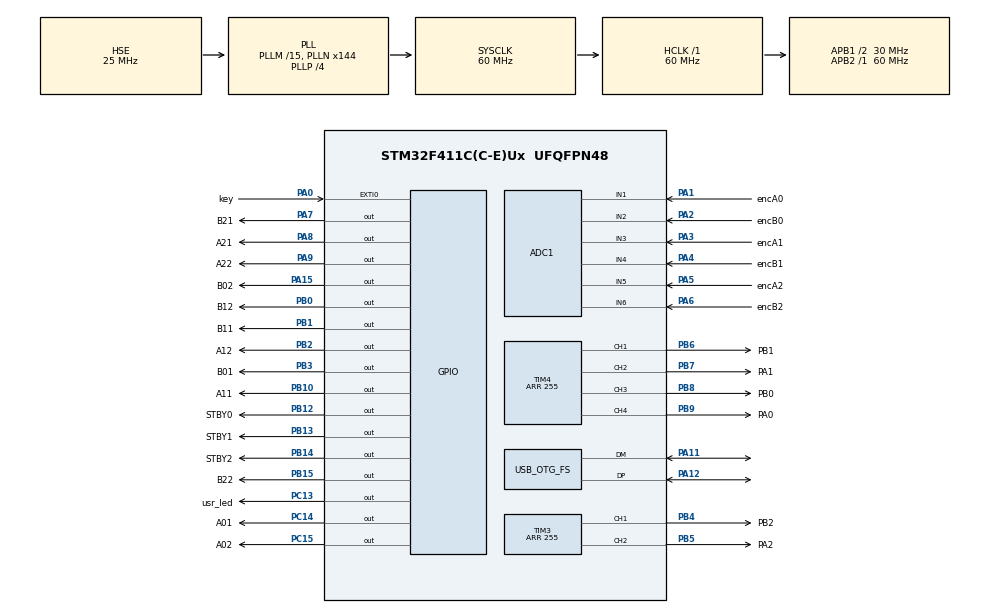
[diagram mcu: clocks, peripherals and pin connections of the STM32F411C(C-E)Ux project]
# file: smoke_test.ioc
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ADC1.Channel-0\#ChannelRegularConversion=ADC_CHANNEL_1
ADC1.NbrOfConversionFlag=1
ADC1.Rank-0\#ChannelRegularConversion=1
ADC1.SamplingTime-0\#ChannelRegularConversion=ADC_SAMPLETIME_3CYCLES
ADC1.master=1
Mcu.Family=STM32F4
Mcu.Name=STM32F411C(C-E)Ux
Mcu.Package=UFQFPN48
NVIC.EXTI0_IRQn=true\:0\:0\:false\:false\:true\:true\:true\:true
NVIC.OTG_FS_IRQn=true\:0\:0\:false\:false\:true\:false\:true\:true
NVIC.PriorityGroup=NVIC_PRIORITYGROUP_4
PA0-WKUP.GPIO_Label=key
PA0-WKUP.GPIO_ModeDefaultEXTI=GPIO_MODE_IT_FALLING
PA0-WKUP.GPIO_PuPd=GPIO_PULLUP
PA0-WKUP.Signal=GPXTI0
PA1.GPIO_Label=encA0
PA1.Signal=ADCx_IN1
PA11.Mode=Device_Only
PA11.Signal=USB_OTG_FS_DM
PA12.Mode=Device_Only
PA12.Signal=USB_OTG_FS_DP
PA13.Mode=Serial_Wire
PA13.Signal=SYS_JTMS-SWDIO
PA14.Mode=Serial_Wire
PA14.Signal=SYS_JTCK-SWCLK
PA15.GPIO_Label=B02
PA15.Signal=GPIO_Output
PA2.GPIO_Label=encB0
PA2.Signal=ADCx_IN2
PA3.GPIO_Label=encA1
PA3.Signal=ADCx_IN3
PA4.GPIO_Label=encB1
PA4.Signal=ADCx_IN4
PA5.GPIO_Label=encA2
PA5.Signal=ADCx_IN5
PA6.GPIO_Label=encB2
PA6.Signal=ADCx_IN6
PA7.GPIO_Label=B21
PA7.Signal=GPIO_Output
PA8.GPIO_Label=A21
PA8.Signal=GPIO_Output
PA9.GPIO_Label=A22
PA9.Signal=GPIO_Output
PB0.GPIO_Label=B12
PB0.Signal=GPIO_Output
PB1.GPIO_Label=B11
PB1.Signal=GPIO_Output
PB10.GPIO_Label=A11
PB10.Signal=GPIO_Output
PB12.GPIO_Label=STBY0
PB12.Signal=GPIO_Output
PB13.GPIO_Label=STBY1
PB13.Signal=GPIO_Output
PB14.GPIO_Label=STBY2
PB14.Signal=GPIO_Output
PB15.GPIO_Label=B22
PB15.Signal=GPIO_Output
PB2.GPIO_Label=A12
PB2.Signal=GPIO_Output
PB3.GPIO_Label=B01
PB3.Signal=GPIO_Output
PB4.GPIO_Label=PB2
PB4.Signal=S_TIM3_CH1
PB5.GPIO_Label=PA2
PB5.Signal=S_TIM3_CH2
PB6.GPIO_Label=PB1
PB6.Signal=S_TIM4_CH1
PB7.GPIO_Label=PA1
PB7.Signal=S_TIM4_CH2
PB8.GPIO_Label=PB0
PB8.Signal=S_TIM4_CH3
PB9.GPIO_Label=PA0
PB9.Signal=S_TIM4_CH4
PC13-ANTI_TAMP.GPIO_Label=usr_led
PC13-ANTI_TAMP.Signal=GPIO_Output
PC14-OSC32_IN.GPIO_Label=A01
PC14-OSC32_IN.Signal=GPIO_Output
PC15-OSC32_OUT.GPIO_Label=A02
PC15-OSC32_OUT.Signal=GPIO_Output
PH0\ -\ OSC_IN.Mode=HSE-External-Oscillator
PH0\ -\ OSC_IN.Signal=RCC_OSC_IN
PH1\ -\ OSC_OUT.Mode=HSE-External-Oscillator
PH1\ -\ OSC_OUT.Signal=RCC_OSC_OUT
ProjectManager.HeapSize=0x200
ProjectManager.StackSize=0x400
ProjectManager.TargetToolchain=CMake
RCC.48MHZClocksFreq_Value=48000000
RCC.AHBFreq_Value=60000000
RCC.APB1CLKDivider=RCC_HCLK_DIV2
RCC.APB1Freq_Value=30000000
RCC.APB1TimFreq_Value=60000000
RCC.APB2Freq_Value=60000000
RCC.APB2TimFreq_Value=60000000
RCC.CortexFreq_Value=60000000
RCC.HCLKFreq_Value=60000000
RCC.HSE_VALUE=25000000
RCC.HSI_VALUE=16000000
RCC.LSE_VALUE=32768
RCC.PLLM=15
RCC.PLLN=144
RCC.PLLP=RCC_PLLP_DIV4
RCC.PLLQ=5
RCC.SYSCLKFreq_VALUE=60000000
RCC.SYSCLKSource=RCC_SYSCLKSOURCE_PLLCLK
RCC.VCOOutputFreq_Value=240000000
SH.ADCx_IN1.0=ADC1_IN1,IN1
SH.ADCx_IN2.0=ADC1_IN2,IN2
SH.ADCx_IN3.0=ADC1_IN3,IN3
SH.ADCx_IN4.0=ADC1_IN4,IN4
SH.ADCx_IN5.0=ADC1_IN5,IN5
SH.ADCx_IN6.0=ADC1_IN6,IN6
SH.S_TIM3_CH1.0=TIM3_CH1,PWM Generation1 CH1
SH.S_TIM3_CH2.0=TIM3_CH2,PWM Generation2 CH2
SH.S_TIM4_CH1.0=TIM4_CH1,PWM Generation1 CH1
SH.S_TIM4_CH2.0=TIM4_CH2,PWM Generation2 CH2
SH.S_TIM4_CH3.0=TIM4_CH3,PWM Generation3 CH3
SH.S_TIM4_CH4.0=TIM4_CH4,PWM Generation4 CH4
TIM3.Channel-PWM\ Generation1\ CH1=TIM_CHANNEL_1
TIM3.Channel-PWM\ Generation2\ CH2=TIM_CHANNEL_2
TIM3.Period=255
TIM4.Channel-PWM\ Generation1\ CH1=TIM_CHANNEL_1
TIM4.Channel-PWM\ Generation2\ CH2=TIM_CHANNEL_2
TIM4.Channel-PWM\ Generation3\ CH3=TIM_CHANNEL_3
TIM4.Channel-PWM\ Generation4\ CH4=TIM_CHANNEL_4
TIM4.Period=255
USB_DEVICE.CLASS_NAME_FS=CDC
USB_DEVICE.VirtualMode=Cdc
USB_DEVICE.VirtualModeFS=Cdc_FS
USB_OTG_FS.VirtualMode=Device_Only
VP_TIM3_VS_ClockSourceINT.Mode=Internal
VP_TIM4_VS_ClockSourceINT.Mode=Internal
VP_USB_DEVICE_VS_USB_DEVICE_CDC_FS.Mode=CDC_FS
board=custom

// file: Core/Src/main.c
/* USER CODE BEGIN Header */
/* USER CODE END Header */
#include "main.h"
#include "usb_device.h"

/* USER CODE BEGIN Includes */
#include "usbd_cdc_if.h"
/* USER CODE END Includes */

ADC_HandleTypeDef hadc1;

TIM_HandleTypeDef htim3;
TIM_HandleTypeDef htim4;

/* USER CODE BEGIN PV */
uint8_t TxBuffer[] = "Hello World! From STM32 USB CDC Device To Virtual COM Port\r\n";
/* USER CODE END PV */

void SystemClock_Config(void);
static void MX_GPIO_Init(void);
static void MX_ADC1_Init(void);
static void MX_TIM3_Init(void);
static void MX_TIM4_Init(void);

/* USER CODE BEGIN 0 */
void USB_CDC_RxHandler(uint8_t* Buf, uint32_t Len)
{
	CDC_Transmit_FS(Buf, (uint16_t)Len);
	HAL_GPIO_TogglePin(usr_led_GPIO_Port, usr_led_Pin);
}

void HAL_GPIO_EXTI_Callback(uint16_t GPIO_Pin)
{
    if(GPIO_Pin == key_Pin) // If The INT Source Is EXTI Line0 (A0 Pin)
    {
    	// bug (need to fix later): for some reason the regardlesss of whether you check in the falling edge or the rising edge
    	// the interrupt only fires when you release the button.
    	HAL_GPIO_TogglePin(usr_led_GPIO_Port, usr_led_Pin); // Toggle The Output (LED) Pin
    }
}
/* USER CODE END 0 */

int main(void)
{

  /* MCU Configuration--------------------------------------------------------*/

  /* Reset of all peripherals, Initializes the Flash interface and the Systick. */
  HAL_Init();

  /* Configure the system clock */
  SystemClock_Config();

  /* Initialize all configured peripherals */
  MX_GPIO_Init();
  MX_ADC1_Init();
  MX_TIM3_Init();
  MX_TIM4_Init();
  MX_USB_DEVICE_Init();
  /* USER CODE BEGIN 2 */
  HAL_GPIO_WritePin(usr_led_GPIO_Port, usr_led_Pin, 1);
  /* USER CODE END 2 */

  /* Infinite loop */
  while (1)
  {

    /* USER CODE BEGIN 3 */
//	  CDC_Transmit_FS(TxBuffer, sizeof(TxBuffer));
//	  HAL_Delay(100);
  }
  /* USER CODE END 3 */
}

void SystemClock_Config(void)
{
  RCC_OscInitTypeDef RCC_OscInitStruct = {0};
  RCC_ClkInitTypeDef RCC_ClkInitStruct = {0};

  /** Configure the main internal regulator output voltage
  */
  __HAL_RCC_PWR_CLK_ENABLE();
  __HAL_PWR_VOLTAGESCALING_CONFIG(PWR_REGULATOR_VOLTAGE_SCALE1);

  /** Initializes the RCC Oscillators according to the specified parameters
  * in the RCC_OscInitTypeDef structure.
  */
  RCC_OscInitStruct.OscillatorType = RCC_OSCILLATORTYPE_HSE;
  RCC_OscInitStruct.HSEState = RCC_HSE_ON;
  RCC_OscInitStruct.PLL.PLLState = RCC_PLL_ON;
  RCC_OscInitStruct.PLL.PLLSource = RCC_PLLSOURCE_HSE;
  RCC_OscInitStruct.PLL.PLLM = 15;
  RCC_OscInitStruct.PLL.PLLN = 144;
  RCC_OscInitStruct.PLL.PLLP = RCC_PLLP_DIV4;
  RCC_OscInitStruct.PLL.PLLQ = 5;
  if (HAL_RCC_OscConfig(&RCC_OscInitStruct) != HAL_OK)
  {
    Error_Handler();
  }

  /** Initializes the CPU, AHB and APB buses clocks
  */
  RCC_ClkInitStruct.ClockType = RCC_CLOCKTYPE_HCLK|RCC_CLOCKTYPE_SYSCLK
                              |RCC_CLOCKTYPE_PCLK1|RCC_CLOCKTYPE_PCLK2;
  RCC_ClkInitStruct.SYSCLKSource = RCC_SYSCLKSOURCE_PLLCLK;
  RCC_ClkInitStruct.AHBCLKDivider = RCC_SYSCLK_DIV1;
  RCC_ClkInitStruct.APB1CLKDivider = RCC_HCLK_DIV2;
  RCC_ClkInitStruct.APB2CLKDivider = RCC_HCLK_DIV1;

  if (HAL_RCC_ClockConfig(&RCC_ClkInitStruct, FLASH_LATENCY_1) != HAL_OK)
  {
    Error_Handler();
  }
}

static void MX_ADC1_Init(void)
{

  ADC_ChannelConfTypeDef sConfig = {0};

  /** Configure the global features of the ADC (Clock, Resolution, Data Alignment and number of conversion)
  */
  hadc1.Instance = ADC1;
  hadc1.Init.ClockPrescaler = ADC_CLOCK_SYNC_PCLK_DIV2;
  hadc1.Init.Resolution = ADC_RESOLUTION_12B;
  hadc1.Init.ScanConvMode = DISABLE;
  hadc1.Init.ContinuousConvMode = DISABLE;
  hadc1.Init.DiscontinuousConvMode = DISABLE;
  hadc1.Init.ExternalTrigConvEdge = ADC_EXTERNALTRIGCONVEDGE_NONE;
  hadc1.Init.ExternalTrigConv = ADC_SOFTWARE_START;
  hadc1.Init.DataAlign = ADC_DATAALIGN_RIGHT;
  hadc1.Init.NbrOfConversion = 1;
  hadc1.Init.DMAContinuousRequests = DISABLE;
  hadc1.Init.EOCSelection = ADC_EOC_SINGLE_CONV;
  if (HAL_ADC_Init(&hadc1) != HAL_OK)
  {
    Error_Handler();
  }

  /** Configure for the selected ADC regular channel its corresponding rank in the sequencer and its sample time.
  */
  sConfig.Channel = ADC_CHANNEL_1;
  sConfig.Rank = 1;
  sConfig.SamplingTime = ADC_SAMPLETIME_3CYCLES;
  if (HAL_ADC_ConfigChannel(&hadc1, &sConfig) != HAL_OK)
  {
    Error_Handler();
  }

}

static void MX_TIM3_Init(void)
{

  TIM_ClockConfigTypeDef sClockSourceConfig = {0};
  TIM_MasterConfigTypeDef sMasterConfig = {0};
  TIM_OC_InitTypeDef sConfigOC = {0};

  htim3.Instance = TIM3;
  htim3.Init.Prescaler = 0;
  htim3.Init.CounterMode = TIM_COUNTERMODE_UP;
  htim3.Init.Period = 255;
  htim3.Init.ClockDivision = TIM_CLOCKDIVISION_DIV1;
  htim3.Init.AutoReloadPreload = TIM_AUTORELOAD_PRELOAD_DISABLE;
  if (HAL_TIM_Base_Init(&htim3) != HAL_OK)
  {
    Error_Handler();
  }
  sClockSourceConfig.ClockSource = TIM_CLOCKSOURCE_INTERNAL;
  if (HAL_TIM_ConfigClockSource(&htim3, &sClockSourceConfig) != HAL_OK)
  {
    Error_Handler();
  }
  if (HAL_TIM_PWM_Init(&htim3) != HAL_OK)
  {
    Error_Handler();
  }
  sMasterConfig.MasterOutputTrigger = TIM_TRGO_RESET;
  sMasterConfig.MasterSlaveMode = TIM_MASTERSLAVEMODE_DISABLE;
  if (HAL_TIMEx_MasterConfigSynchronization(&htim3, &sMasterConfig) != HAL_OK)
  {
    Error_Handler();
  }
  sConfigOC.OCMode = TIM_OCMODE_PWM1;
  sConfigOC.Pulse = 0;
  sConfigOC.OCPolarity = TIM_OCPOLARITY_HIGH;
  sConfigOC.OCFastMode = TIM_OCFAST_DISABLE;
  if (HAL_TIM_PWM_ConfigChannel(&htim3, &sConfigOC, TIM_CHANNEL_1) != HAL_OK)
  {
    Error_Handler();
  }
  if (HAL_TIM_PWM_ConfigChannel(&htim3, &sConfigOC, TIM_CHANNEL_2) != HAL_OK)
  {
    Error_Handler();
  }
  HAL_TIM_MspPostInit(&htim3);

}

static void MX_TIM4_Init(void)
{

  TIM_ClockConfigTypeDef sClockSourceConfig = {0};
  TIM_MasterConfigTypeDef sMasterConfig = {0};
  TIM_OC_InitTypeDef sConfigOC = {0};

  htim4.Instance = TIM4;
  htim4.Init.Prescaler = 0;
  htim4.Init.CounterMode = TIM_COUNTERMODE_UP;
  htim4.Init.Period = 255;
  htim4.Init.ClockDivision = TIM_CLOCKDIVISION_DIV1;
  htim4.Init.AutoReloadPreload = TIM_AUTORELOAD_PRELOAD_DISABLE;
  if (HAL_TIM_Base_Init(&htim4) != HAL_OK)
  {
    Error_Handler();
  }
  sClockSourceConfig.ClockSource = TIM_CLOCKSOURCE_INTERNAL;
  if (HAL_TIM_ConfigClockSource(&htim4, &sClockSourceConfig) != HAL_OK)
  {
    Error_Handler();
  }
  if (HAL_TIM_PWM_Init(&htim4) != HAL_OK)
  {
    Error_Handler();
  }
  sMasterConfig.MasterOutputTrigger = TIM_TRGO_RESET;
  sMasterConfig.MasterSlaveMode = TIM_MASTERSLAVEMODE_DISABLE;
  if (HAL_TIMEx_MasterConfigSynchronization(&htim4, &sMasterConfig) != HAL_OK)
  {
    Error_Handler();
  }
  sConfigOC.OCMode = TIM_OCMODE_PWM1;
  sConfigOC.Pulse = 0;
  sConfigOC.OCPolarity = TIM_OCPOLARITY_HIGH;
  sConfigOC.OCFastMode = TIM_OCFAST_DISABLE;
  if (HAL_TIM_PWM_ConfigChannel(&htim4, &sConfigOC, TIM_CHANNEL_1) != HAL_OK)
  {
    Error_Handler();
  }
  if (HAL_TIM_PWM_ConfigChannel(&htim4, &sConfigOC, TIM_CHANNEL_2) != HAL_OK)
  {
    Error_Handler();
  }
  if (HAL_TIM_PWM_ConfigChannel(&htim4, &sConfigOC, TIM_CHANNEL_3) != HAL_OK)
  {
    Error_Handler();
  }
  if (HAL_TIM_PWM_ConfigChannel(&htim4, &sConfigOC, TIM_CHANNEL_4) != HAL_OK)
  {
    Error_Handler();
  }
  HAL_TIM_MspPostInit(&htim4);

}

static void MX_GPIO_Init(void)
{
  GPIO_InitTypeDef GPIO_InitStruct = {0};

  /* GPIO Ports Clock Enable */
  __HAL_RCC_GPIOC_CLK_ENABLE();
  __HAL_RCC_GPIOH_CLK_ENABLE();
  __HAL_RCC_GPIOA_CLK_ENABLE();
  __HAL_RCC_GPIOB_CLK_ENABLE();

  /*Configure GPIO pin Output Level */
  HAL_GPIO_WritePin(GPIOC, usr_led_Pin|A01_Pin|A02_Pin, GPIO_PIN_RESET);

  /*Configure GPIO pin Output Level */
  HAL_GPIO_WritePin(GPIOA, B21_Pin|A21_Pin|A22_Pin|B02_Pin, GPIO_PIN_RESET);

  /*Configure GPIO pin Output Level */
  HAL_GPIO_WritePin(GPIOB, B12_Pin|B11_Pin|A12_Pin|A11_Pin
                          |STBY0_Pin|STBY1_Pin|STBY2_Pin|B22_Pin
                          |B01_Pin, GPIO_PIN_RESET);

  /*Configure GPIO pins : usr_led_Pin A01_Pin A02_Pin */
  GPIO_InitStruct.Pin = usr_led_Pin|A01_Pin|A02_Pin;
  GPIO_InitStruct.Mode = GPIO_MODE_OUTPUT_PP;
  GPIO_InitStruct.Pull = GPIO_NOPULL;
  GPIO_InitStruct.Speed = GPIO_SPEED_FREQ_LOW;
  HAL_GPIO_Init(GPIOC, &GPIO_InitStruct);

  /*Configure GPIO pin : key_Pin */
  GPIO_InitStruct.Pin = key_Pin;
  GPIO_InitStruct.Mode = GPIO_MODE_IT_FALLING;
  GPIO_InitStruct.Pull = GPIO_PULLUP;
  HAL_GPIO_Init(key_GPIO_Port, &GPIO_InitStruct);

  /*Configure GPIO pins : B21_Pin A21_Pin A22_Pin B02_Pin */
  GPIO_InitStruct.Pin = B21_Pin|A21_Pin|A22_Pin|B02_Pin;
  GPIO_InitStruct.Mode = GPIO_MODE_OUTPUT_PP;
  GPIO_InitStruct.Pull = GPIO_NOPULL;
  GPIO_InitStruct.Speed = GPIO_SPEED_FREQ_LOW;
  HAL_GPIO_Init(GPIOA, &GPIO_InitStruct);

  /*Configure GPIO pins : B12_Pin B11_Pin A12_Pin A11_Pin
                           STBY0_Pin STBY1_Pin STBY2_Pin B22_Pin
                           B01_Pin */
  GPIO_InitStruct.Pin = B12_Pin|B11_Pin|A12_Pin|A11_Pin
                          |STBY0_Pin|STBY1_Pin|STBY2_Pin|B22_Pin
                          |B01_Pin;
  GPIO_InitStruct.Mode = GPIO_MODE_OUTPUT_PP;
  GPIO_InitStruct.Pull = GPIO_NOPULL;
  GPIO_InitStruct.Speed = GPIO_SPEED_FREQ_LOW;
  HAL_GPIO_Init(GPIOB, &GPIO_InitStruct);

  /* EXTI interrupt init*/
  HAL_NVIC_SetPriority(EXTI0_IRQn, 0, 0);
  HAL_NVIC_EnableIRQ(EXTI0_IRQn);

}

void Error_Handler(void)
{
}
